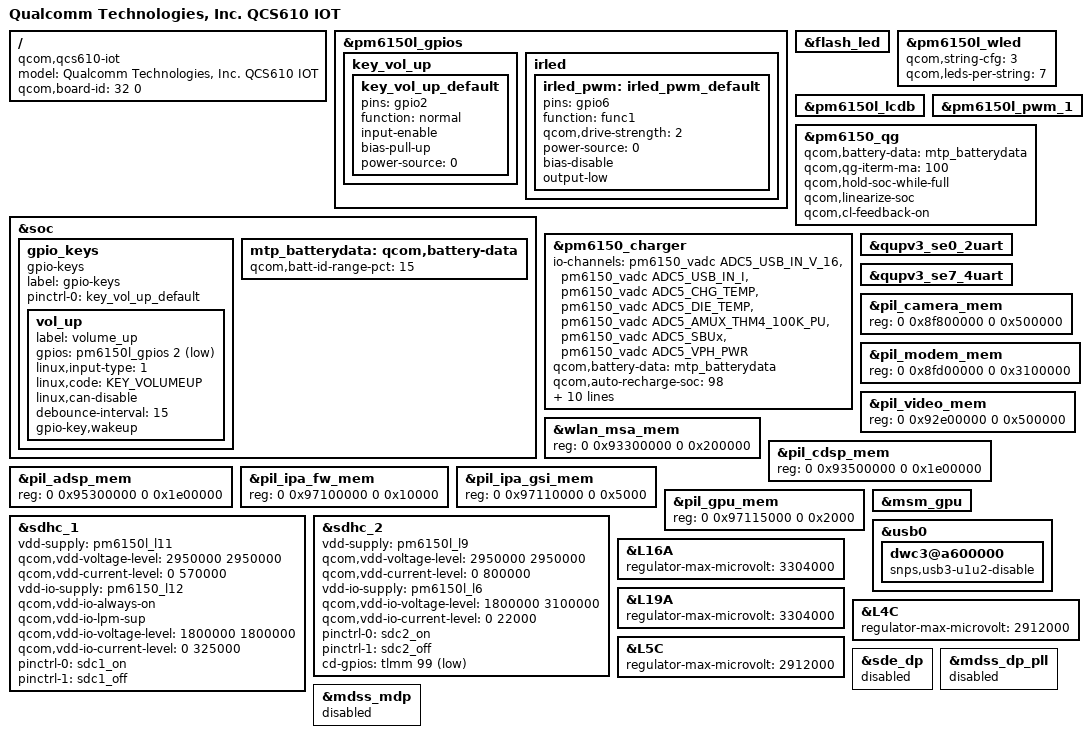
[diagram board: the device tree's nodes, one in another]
#include <dt-bindings/gpio/gpio.h>
#include <dt-bindings/iio/qcom,spmi-vadc.h>
#include <dt-bindings/input/input.h>

#include <dt-bindings/clock/qcom,rpmh.h>
#include <dt-bindings/clock/qcom,gcc-sm6150.h>
#include <dt-bindings/clock/qcom,camcc-sm6150.h>
#include <dt-bindings/clock/qcom,dispcc-sm6150.h>
#include <dt-bindings/clock/qcom,gpucc-sm6150.h>

/ {
	model = "Qualcomm Technologies, Inc. QCS610 IOT";
	compatible = "qcom,qcs610-iot", "qcom,qcs610", "qcom,iot";
	qcom,board-id = <32 0>;
};

&pm6150l_gpios {
	key_vol_up {
		key_vol_up_default: key_vol_up_default {
			pins = "gpio2";
			function = "normal";
			input-enable;
			bias-pull-up;
			power-source = <0>;
		};
	};

	irled {
		irled_pwm: irled_pwm_default {
			pins = "gpio6";
			function = "func1";
			qcom,drive-strength = <2>;
			power-source = <0>;
			bias-disable;
			output-low;
		};
	};
};

&soc {
	gpio_keys {
		compatible = "gpio-keys";
		label = "gpio-keys";

		pinctrl-names = "default";
		pinctrl-0 = <&key_vol_up_default>;

		vol_up {
			label = "volume_up";
			gpios = <&pm6150l_gpios 2 GPIO_ACTIVE_LOW>;
			linux,input-type = <1>;
			linux,code = <KEY_VOLUMEUP>;
			linux,can-disable;
			debounce-interval = <15>;
			gpio-key,wakeup;
		};
	};

	mtp_batterydata: qcom,battery-data {
		qcom,batt-id-range-pct = <15>;
		#include "qg-batterydata-alium-3600mah.dtsi"
		#include "qg-batterydata-mlp356477-2800mah.dtsi"
	};


};

&flash_led {
	status = "ok";
};

&pm6150l_wled {
	qcom,string-cfg= <3>;
	qcom,leds-per-string = <7>;
	status = "ok";
};

&pm6150l_lcdb {
	status = "ok";
};

&pm6150l_pwm_1 {
	status = "okay";
};

&pm6150_qg {
	qcom,battery-data = <&mtp_batterydata>;
	qcom,qg-iterm-ma = <100>;
	qcom,hold-soc-while-full;
	qcom,linearize-soc;
	qcom,cl-feedback-on;
};

&pm6150_charger {
	io-channels = <&pm6150_vadc ADC5_USB_IN_V_16>,
		      <&pm6150_vadc ADC5_USB_IN_I>,
		      <&pm6150_vadc ADC5_CHG_TEMP>,
		      <&pm6150_vadc ADC5_DIE_TEMP>,
		      <&pm6150_vadc ADC5_AMUX_THM4_100K_PU>,
		      <&pm6150_vadc ADC5_SBUx>,
		      <&pm6150_vadc ADC5_VPH_PWR>;
	io-channel-names = "usb_in_voltage",
			   "usb_in_current",
			   "chg_temp",
			   "die_temp",
			   "conn_temp",
			   "sbux_res",
			   "vph_voltage";
	qcom,battery-data = <&mtp_batterydata>;
	qcom,auto-recharge-soc = <98>;
	qcom,step-charging-enable;
	qcom,sw-jeita-enable;
	qcom,fcc-stepping-enable;
	qcom,suspend-input-on-debug-batt;
	qcom,sec-charger-config = <3>;
	qcom,thermal-mitigation = <4200000 3500000 3000000
			2500000 2000000 1500000 1000000 500000>;
	dpdm-supply = <&qusb_phy0>;
	qcom,charger-temp-max = <800>;
	qcom,smb-temp-max = <800>;
};

&qupv3_se0_2uart {
	status = "ok";
};

&qupv3_se7_4uart {
	status = "ok";
};

&pil_camera_mem {
	reg = <0 0x8f800000 0 0x500000>;
};

&pil_modem_mem {
	reg = <0 0x8fd00000 0 0x3100000>;
};

&pil_video_mem {
	reg = <0 0x92e00000 0 0x500000>;
};

&wlan_msa_mem {
	reg = <0 0x93300000 0 0x200000>;
};

&pil_cdsp_mem {
	reg = <0 0x93500000 0 0x1e00000>;
};

&pil_adsp_mem {
	reg = <0 0x95300000 0 0x1e00000>;
};

&pil_ipa_fw_mem {
	reg = <0 0x97100000 0 0x10000>;
};

&pil_ipa_gsi_mem {
	reg = <0 0x97110000 0 0x5000>;
};

&pil_gpu_mem {
	reg = <0 0x97115000 0 0x2000>;
};

&msm_gpu {
	/delete-node/qcom,gpu-mempools;
};

&sdhc_1 {
	vdd-supply = <&pm6150l_l11>;
	qcom,vdd-voltage-level = <2950000 2950000>;
	qcom,vdd-current-level = <0 570000>;

	vdd-io-supply = <&pm6150_l12>;
	qcom,vdd-io-always-on;
	qcom,vdd-io-lpm-sup;
	qcom,vdd-io-voltage-level = <1800000 1800000>;
	qcom,vdd-io-current-level = <0 325000>;

	pinctrl-names = "default", "sleep";
	pinctrl-0 = <&sdc1_on>;
	pinctrl-1 = <&sdc1_off>;

	status = "ok";
};

&sdhc_2 {
	vdd-supply = <&pm6150l_l9>;
	qcom,vdd-voltage-level = <2950000 2950000>;
	qcom,vdd-current-level = <0 800000>;

	vdd-io-supply = <&pm6150l_l6>;
	qcom,vdd-io-voltage-level = <1800000 3100000>;
	qcom,vdd-io-current-level = <0 22000>;

	pinctrl-names = "default", "sleep";
	pinctrl-0 = <&sdc2_on>;
	pinctrl-1 = <&sdc2_off>;

	cd-gpios = <&tlmm 99 GPIO_ACTIVE_LOW>;

	status = "ok";
};

&usb0 {
	dwc3@a600000 {
		snps,usb3-u1u2-disable;
	};
};

&L16A {
	regulator-max-microvolt = <3304000>;
};

&L19A {
	regulator-max-microvolt = <3304000>;
};

&L4C {
	regulator-max-microvolt = <2912000>;
};

&L5C {
	regulator-max-microvolt = <2912000>;
};

&sde_dp {
	status="disabled";
};

&mdss_dp_pll {
	status="disabled";
};

&mdss_mdp {
	status="disabled";
};
